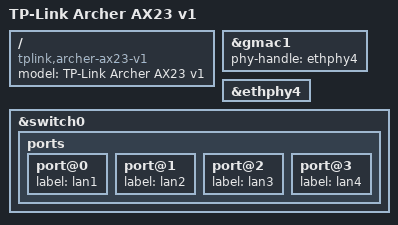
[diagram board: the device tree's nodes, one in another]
// SPDX-License-Identifier: GPL-2.0-or-later OR MIT

#include "mt7621_tplink_archer-ax23.dtsi"

/ {
	compatible = "tplink,archer-ax23-v1", "mediatek,mt7621-soc";
	model = "TP-Link Archer AX23 v1";
};

&gmac1 {
	phy-handle = <&ethphy4>;
};

&ethphy4 {
	/delete-property/ interrupts;
};

&switch0 {
	ports {
		port@0 {
			status = "okay";
			label = "lan1";
		};

		port@1 {
			status = "okay";
			label = "lan2";
		};

		port@2 {
			status = "okay";
			label = "lan3";
		};

		port@3 {
			status = "okay";
			label = "lan4";
		};
	};
};
